# CH32V00xxx register map
Vendor: WCH Ltd.; File version: 1.1
Registers are 32-bit, read-write, reset 0x0 unless marked. A register's access mark holds for its fields unless they carry their own. Offsets are from the block's base; [hi:lo] are bit positions; {n}, {i} and the like mark numbered series.

## USART1 — Universal synchronous asynchronous receiver transmitter
Base 0x40013800
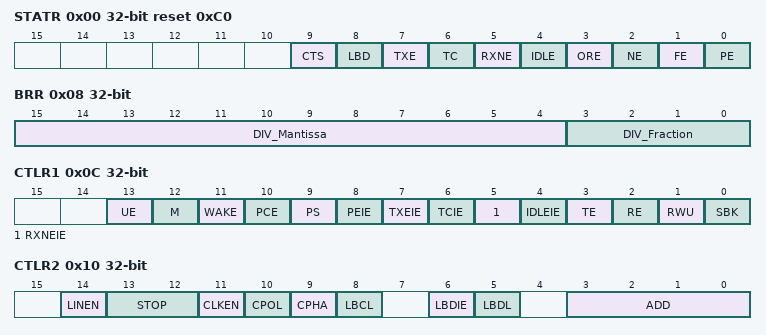
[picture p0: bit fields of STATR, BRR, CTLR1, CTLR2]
0x00 STATR access per field reset 0xC0 — Status register
  [9] CTS rw — CTS flag
  [8] LBD rw — LIN break detection flag
  [7] TXE ro — Transmit data register empty
  [6] TC rw — Transmission complete
  [5] RXNE rw — Read data register not empty
  [4] IDLE ro — IDLE line detected
  [3] ORE ro — Overrun error
  [2] NE ro — Noise error flag
  [1] FE ro — Framing error
  [0] PE ro — Parity error
0x04 DATAR — Data register
  [8:0] DR — Data value
0x08 BRR — Baud rate register
  [15:4] DIV_Mantissa — mantissa of USARTDIV
  [3:0] DIV_Fraction — fraction of USARTDIV
0x0C CTLR1 — Control register 1
  [13] UE — USART enable
  [12] M — Word length
  [11] WAKE — Wakeup method
  [10] PCE — Parity control enable
  [9] PS — Parity selection
  [8] PEIE — PE interrupt enable
  [7] TXEIE — TXE interrupt enable
  [6] TCIE — Transmission complete interrupt enable
  [5] RXNEIE — RXNE interrupt enable
  [4] IDLEIE — IDLE interrupt enable
  [3] TE — Transmitter enable
  [2] RE — Receiver enable
  [1] RWU — Receiver wakeup
  [0] SBK — Send break
0x10 CTLR2 — Control register 2
  [14] LINEN — LIN mode enable
  [13:12] STOP — STOP bits
  [11] CLKEN — Clock enable
  [10] CPOL — Clock polarity
  [9] CPHA — Clock phase
  [8] LBCL — Last bit clock pulse
  [6] LBDIE — LIN break detection interrupt enable
  [5] LBDL — lin break detection length
  [3:0] ADD — Address of the USART node
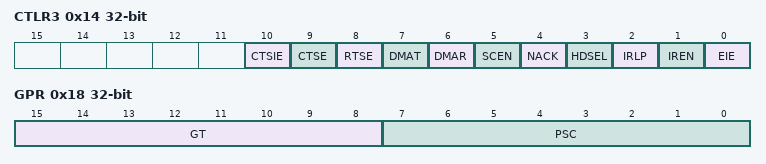
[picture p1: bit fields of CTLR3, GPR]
0x14 CTLR3 — Control register 3
  [10] CTSIE — CTS interrupt enable
  [9] CTSE — CTS enable
  [8] RTSE — RTS enable
  [7] DMAT — DMA enable transmitter
  [6] DMAR — DMA enable receiver
  [5] SCEN — Smartcard mode enable
  [4] NACK — Smartcard NACK enable
  [3] HDSEL — Half-duplex selection
  [2] IRLP — IrDA low-power
  [1] IREN — IrDA mode enable
  [0] EIE — Error interrupt enable
0x18 GPR — Guard time and prescaler register
  [15:8] GT — Guard time value
  [7:0] PSC — Prescaler value

## DBG — Debug support
Base 0xE000D000
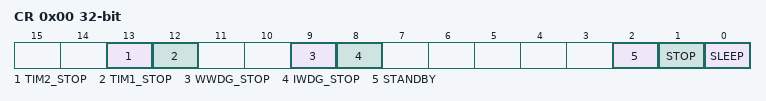
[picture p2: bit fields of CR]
0x00 CR — DBGMCU_CFGR1
  [13] TIM2_STOP
  [12] TIM1_STOP
  [9] WWDG_STOP
  [8] IWDG_STOP
  [2] STANDBY — Debug standby mode
  [1] STOP — Debug stop mode
  [0] SLEEP — Debug Sleep mode

## ESIG — Device electronic signature
Base 0x1FFFF7E0
0x00 FLACAP 16-bit ro — Flash capacity register
  [15:0] F_SIZE_15_0 — Flash size
{0x4+4i} UNIID{i} ro (i=1..3) — Unique identity {i}
  [31:0] U_ID — Unique identity[{32i-1}:{32i-32}]

## FLASH
Base 0x40022000
0x00 ACTLR — Flash key register
  [1:0] LATENCY — Number of FLASH wait states
0x04 KEYR wo — Flash key register
  [31:0] KEYR — FPEC key
0x08 OBKEYR wo — Flash option key register
  [31:0] OPTKEY — Option byte key
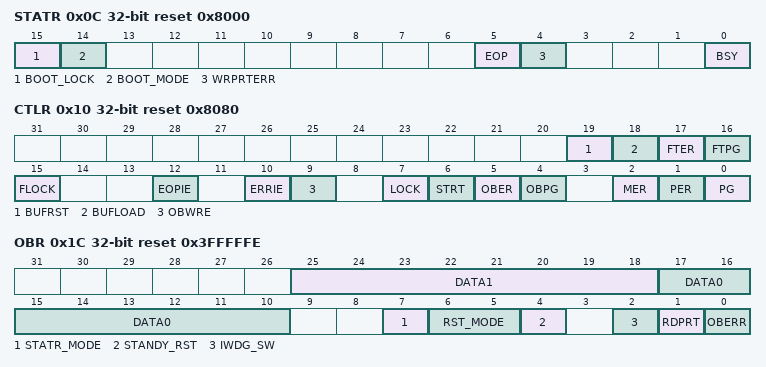
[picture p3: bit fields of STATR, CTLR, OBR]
0x0C STATR access per field reset 0x8000 — Status register
  [15] BOOT_LOCK rw
  [14] BOOT_MODE rw
  [5] EOP rw — End of operation
  [4] WRPRTERR rw — Write protection error
  [0] BSY ro — Busy
0x10 CTLR reset 0x8080 — Control register
  [19] BUFRST — Buffer reset
  [18] BUFLOAD — Buffer load
  [17] FTER — Fast erase
  [16] FTPG — Fast programming
  [15] FLOCK — Fast programmable lock
  [12] EOPIE — End of operation interrupt enable
  [10] ERRIE — Error interrupt enable
  [9] OBWRE — Option bytes write enable
  [7] LOCK
  [6] STRT — Start
  [5] OBER — Option byte erase
  [4] OBPG — Option byte programming
  [2] MER — Mass Erase
  [1] PER — Page Erase
  [0] PG — Programming
0x14 ADDR wo — Flash address register
  [31:0] FAR — Flash Address
0x1C OBR ro reset 0x3FFFFFE — Option byte register
  [25:18] DATA1
  [17:10] DATA0
  [7] STATR_MODE
  [6:5] RST_MODE — CFG_RST_MODE
  [4] STANDY_RST
  [2] IWDG_SW
  [1] RDPRT — Read protection
  [0] OBERR — Option byte error
0x20 WPR ro reset 0xFFFFFFFF — Write protection register
  [15:0] WRP — Write protect
0x24 MODEKEYR wo — Mode select register
  [31:0] MODEKEYR — Mode select
0x28 BOOT_MODEKEYP wo — Boot mode key register
  [31:0] MODEKEYR — Boot mode key

## PFIC — Programmable Fast Interrupt Controller
Base 0xE000E000
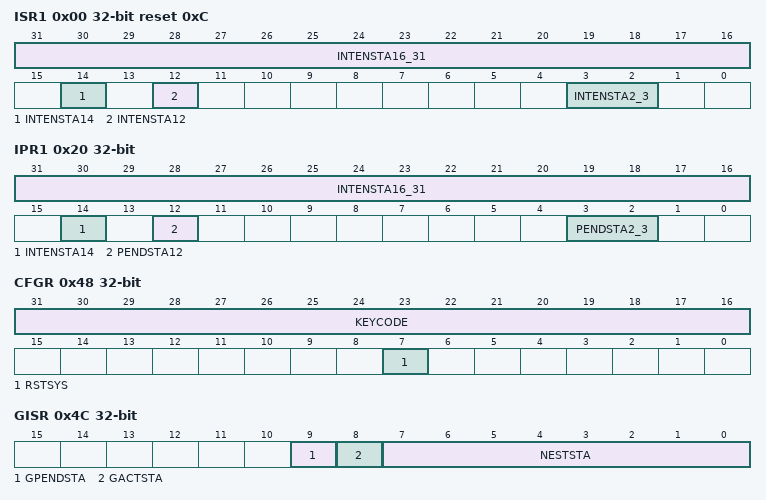
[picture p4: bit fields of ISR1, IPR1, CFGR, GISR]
0x00 ISR1 ro reset 0xC — Interrupt Status Register
  [31:16] INTENSTA16_31 — Interrupt ID Status
  [14] INTENSTA14 — Interrupt ID Status
  [12] INTENSTA12 — Interrupt ID Status
  [3:2] INTENSTA2_3 — Interrupt ID Status
0x04 ISR2 ro — Interrupt Status Register
  [6:0] INTENSTA — Interrupt ID Status
0x20 IPR1 ro — Interrupt Pending Register
  [31:16] INTENSTA16_31 — PENDSTA
  [14] INTENSTA14 — PENDSTA
  [12] PENDSTA12 — PENDSTA
  [3:2] PENDSTA2_3 — PENDSTA
0x24 IPR2 ro — Interrupt Pending Register
  [6:0] PENDSTA32_38 — PENDSTA
0x40 ITHRESDR — Interrupt Priority Register
  [7:0] THRESHOLD
0x48 CFGR wo — Interrupt Config Register
  [31:16] KEYCODE
  [7] RSTSYS — RESET System
0x4C GISR ro — Interrupt Global Register
  [9] GPENDSTA, [8] GACTSTA, [7:0] NESTSTA
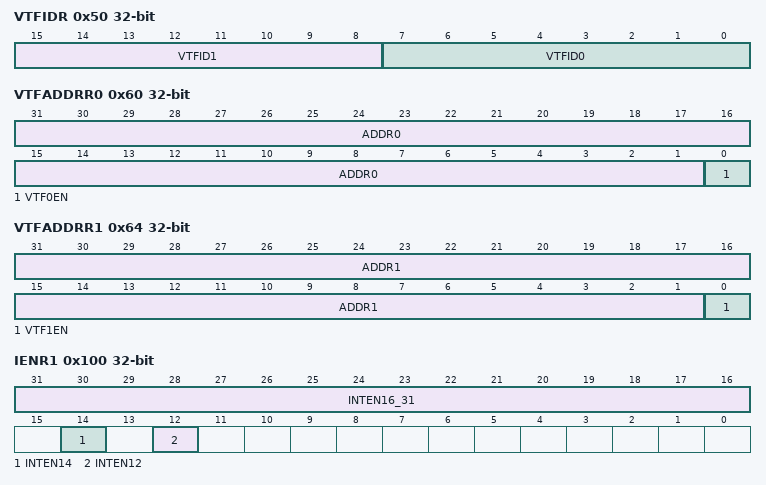
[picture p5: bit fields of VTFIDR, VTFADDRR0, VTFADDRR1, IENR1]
0x50 VTFIDR — ID Config Register
  [15:8] VTFID1, [7:0] VTFID0
0x60 VTFADDRR0 — Interrupt 0 address Register
  [31:1] ADDR0, [0] VTF0EN
0x64 VTFADDRR1 — Interrupt 1 address Register
  [31:1] ADDR1, [0] VTF1EN
0x100 IENR1 wo — Interrupt Setting Register
  [31:16] INTEN16_31, [14] INTEN14, [12] INTEN12
0x104 IENR2 wo — Interrupt Setting Register
  [6:0] INTEN — INTEN32_38
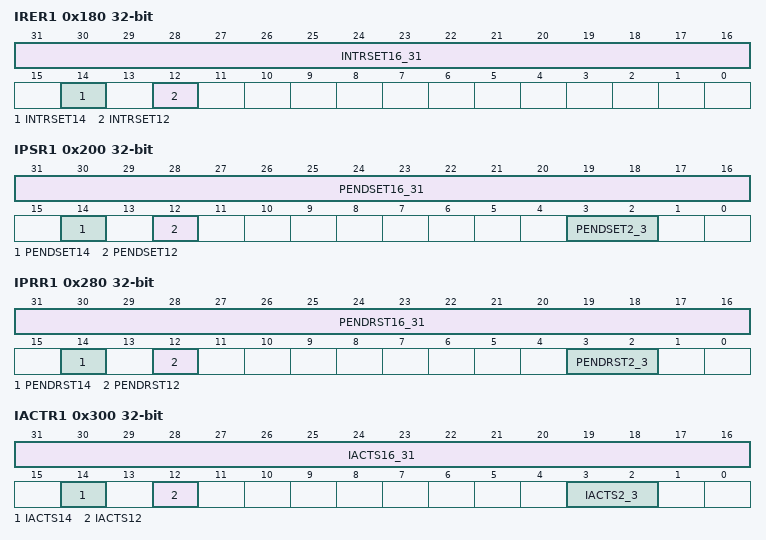
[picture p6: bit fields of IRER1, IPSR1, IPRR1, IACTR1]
0x180 IRER1 wo — Interrupt Clear Register
  [31:16] INTRSET16_31, [14] INTRSET14, [12] INTRSET12
0x184 IRER2 wo — Interrupt Clear Register
  [6:0] INTRSET38_32
0x200 IPSR1 wo — Interrupt Pending Register
  [31:16] PENDSET16_31 — PENDSET
  [14] PENDSET14 — PENDSET
  [12] PENDSET12 — PENDSET
  [3:2] PENDSET2_3 — PENDSET
0x204 IPSR2 wo — Interrupt Pending Register
  [6:0] PENDSET32_38
0x280 IPRR1 wo — Interrupt Pending Clear Register
  [31:16] PENDRST16_31 — PENDRESET
  [14] PENDRST14 — PENDRESET
  [12] PENDRST12 — PENDRESET
  [3:2] PENDRST2_3 — PENDRESET
0x284 IPRR2 wo — Interrupt Pending Clear Register
  [6:0] PENDRST32_38 — PENDRESET32_38
0x300 IACTR1 wo — Interrupt ACTIVE Register
  [31:16] IACTS16_31 — IACTS
  [14] IACTS14 — IACTS
  [12] IACTS12 — IACTS
  [3:2] IACTS2_3 — IACTS
0x304 IACTR2 wo — Interrupt ACTIVE Register
  [6:0] IACTS
{0x400+i} IPRIOR{i} 8-bit (i=0..63) — Interrupt Priority Register
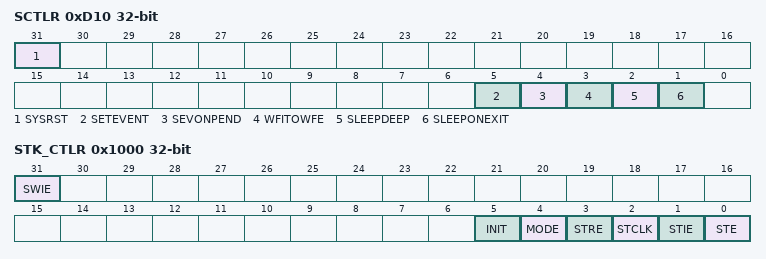
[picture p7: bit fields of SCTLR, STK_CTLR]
0xD10 SCTLR — System Control Register
  [31] SYSRST — SYSRESET
  [5] SETEVENT
  [4] SEVONPEND
  [3] WFITOWFE
  [2] SLEEPDEEP
  [1] SLEEPONEXIT
0x1000 STK_CTLR — System counter control register
  [31] SWIE — System software triggered interrupts enable
  [5] INIT — System Initialization update
  [4] MODE — System Mode
  [3] STRE — System reload register
  [2] STCLK — System selects the clock source
  [1] STIE — System counter interrupt enable
  [0] STE — System counter enable
0x1004 STK_SR — System START
  [0] CNTIF
0x1008 STK_CNTL — System counter low register
  [31:0] CNT
0x1010 STK_CMPLR — System compare low register
  [31:0] CMP
